# RZT2ME register map
Vendor: Renesas Electronics Corporation; Series: RZT; File version: 1.00.00
CPU: other r0p0, little endian, MPU, no FPU, VTOR, 4 interrupt priority bits, 624 interrupts
Registers are 32-bit, read-write, reset 0x0 unless marked. A register's access mark holds for its fields unless they carry their own. Offsets are from the block's base; [hi:lo] are bit positions; {n}, {i} and the like mark numbered series; 'fields as' and 'values as' point back to an identical list.

## PTADR — Port Address Selection
Base 0x81030C00
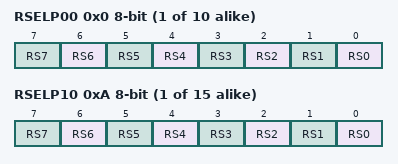
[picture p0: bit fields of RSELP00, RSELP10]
{0x0+i} RSELP0{i} (i=0..9) 8-bit — Port {i} Region Select Register
  [all] fields
    0=Safety region (Address is 0x8103_0xxx); 1=Non safety region (Address is 0x800A_0xxx)
  [n] RS{n} (n=0..7) — Pm_n pin I/O port registers Region Select (n = bit position)
{0x0+i} RSELP{i} (i=10..24) 8-bit — Port {i} Region Select Register
  fields as RSELP00

## SYSC_S — Register Write Protection for Safety Area
Base 0x81280000
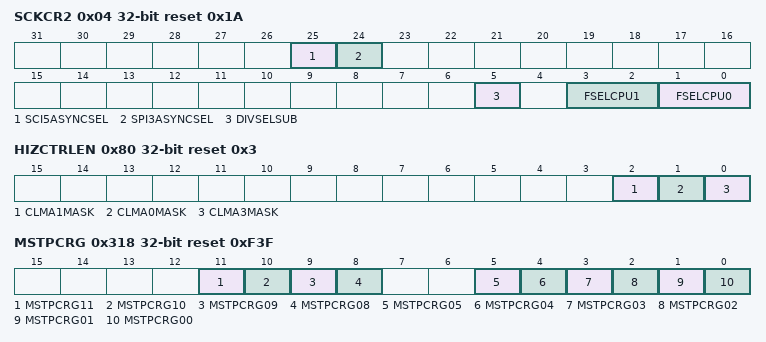
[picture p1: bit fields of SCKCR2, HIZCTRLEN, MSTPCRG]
0x04 SCKCR2 reset 0x1A — System Clock Control Register 2
  [25] SCI5ASYNCSEL — Select clock frequency when asynchronous serial clock is selected in SCI5
    0=75.0 MHz; 1=96.0 MHz
  [24] SPI3ASYNCSEL — Select clock frequency when asynchronous serial clock is selected in SPI3
    0=75.0 MHz; 1=96.0 MHz
  [5] DIVSELSUB — Select the base clock frequency for peripheral module.
  [3:2] FSELCPU1 — Set the frequency of the clock provided to Coretex-R52 CPU1 in combination with bit 5 (DIVSELSUB).
  [1:0] FSELCPU0 — Set the frequency of the clock provided to Coretex-R52 CPU0 in combination with bit 5 (DIVSELSUB). The combination is shown below.
0x20 PLL0MON ro reset 0x1 — PLL0 Monitor Register
  [0] PLL0MON — PLL0 Lock State Monitor
    0=PLL0 is not locked; 1=PLL0 is locked
0x40 PLL1MON ro reset 0x1 — PLL1 Monitor Register
  [0] PLL1MON — PLL1 Lock State Monitor
    0=PLL1 is not locked; 1=PLL1 is locked
0x50 PLL1EN reset 0x1 — PLL1 Enable Register
  [0] PLL1EN — PLL1 Enable
    0=PLL1 is in standby state; 1=PLL1 is in normal state
0x70 LOCOCR — Low-Speed On-Chip Oscillator Control Register
  [0] LCSTP — LOCO Stop
    0=Stop; 1=Run
0x80 HIZCTRLEN reset 0x3 — High-Impedance Control Enable Register
  [2] CLMA1MASK — CLMA1 error mask to POE3 and POEG
    0=CLMA1 error is not transferred to POE3 and POEG; 1=CLMA1 error is transferred to POE3 and POEG
  [1] CLMA0MASK — CLMA0 error mask to POE3 and POEG
    0=CLMA0 error is not transferred to POE3 and POEG; 1=CLMA0 error is transferred to POE3 and POEG
  [0] CLMA3MASK — CLMA3 error mask to POE3 and POEG
    0=CLMA3 error is not transferred to POE3 and POEG; 1=CLMA3 error is transferred to POE3 and POEG
0x210 SWRSYS wo — System Software Reset Register
  [31:0] SWR — System Software Reset
0x220 SWRCPU0 — CPU0 Software Reset Register
  [31:0] SWR — CPU0 Software Reset
0x230 SWRCPU1 reset 0x1 — CPU1 Software Reset Register
  [31:0] SWR — CPU1 Software Reset
0x314 MSTPCRF — Module Stop Control Register F
  [0] MSTPCRF00 — Trace Clock for Debugging Interface Module Stop
    0=Release from the module-stop state; 1=Transition to the module-stop state is made
0x318 MSTPCRG reset 0xF3F — Module Stop Control Register G
  [all] fields
    values as MSTPCRF.MSTPCRF00
  [11] MSTPCRG11 — CLMA2 Module Stop
  [10] MSTPCRG10 — CLMA1 Module Stop
  [9] MSTPCRG09 — CLMA0 Module Stop
  [8] MSTPCRG08 — CLMA3 Module Stop
  [5] MSTPCRG05 — RTC Module Stop
  [4] MSTPCRG04 — CRC Unit 1 Module Stop
  [3] MSTPCRG03 — GPT Unit 2 Module Stop
  [2] MSTPCRG02 — SPI Unit 3 Module Stop
  [1] MSTPCRG01 — IIC Unit 2 Module Stop
  [0] MSTPCRG00 — SCI Unit 5 Module Stop
0x31C MSTPCRH — Module Stop Control Register H
  [1] MSTPCRH01 — CPU1 Module Stop
    values as MSTPCRF.MSTPCRF00

## CLMA0 — Clock Monitor Circuit 0
Base 0x81280800
Same registers: CLMA1 0x81280820, CLMA2 0x81280840, CLMA3 0x81280860
0x00 CTL0 8-bit — CLMA Control Register 0
  [0] CLME — Clock Monitor m Enable (m = 0 to 3)
    0=Disables CLMAm operation; 1=Enables CLMAm operation
0x08 CMPL 16-bit reset 0x1 — CLMA Compare Register L
  [11:0] CMPL — Clock Monitor m Compare L (m = 0 to 3)
0x0C CMPH 16-bit reset 0x3FF — CLMA Compare Register H
  [11:0] CMPH — Clock Monitor m Compare H (m = 0 to 3)
0x10 PCMD 8-bit wo — CLMA Command Register
0x14 PROTSR 8-bit ro — CLMA Protection Status Register
  [0] PRERR — CLMAm Error (m = 0 to 3)
    0=No protection error occurred; 1=A protection error occurred
